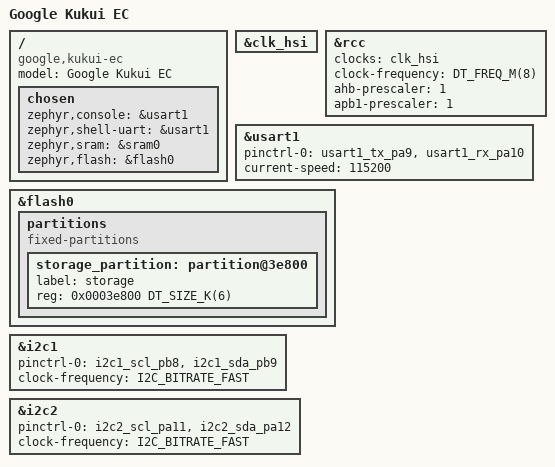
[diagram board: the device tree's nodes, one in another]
/*
 * Copyright (c) 2019 The Chromium OS Authors
 *
 * SPDX-License-Identifier: Apache-2.0
 */

/dts-v1/;
#include <st/f0/stm32f098Xc.dtsi>
#include <st/f0/stm32f098rchx-pinctrl.dtsi>

/ {
	model = "Google Kukui EC";
	compatible = "google,kukui-ec", "st,stm32f098";

	chosen {
		zephyr,console = &usart1;
		zephyr,shell-uart = &usart1;
		zephyr,sram = &sram0;
		zephyr,flash = &flash0;
	};
};

&clk_hsi {
	status = "okay";
};

&rcc {
	clocks = <&clk_hsi>;
	clock-frequency = <DT_FREQ_M(8)>;
	ahb-prescaler = <1>;
	apb1-prescaler = <1>;
};

&usart1 {
	pinctrl-0 = <&usart1_tx_pa9 &usart1_rx_pa10>;
	pinctrl-names = "default";
	current-speed = <115200>;
	status = "okay";
};

&flash0 {
	partitions {
		compatible = "fixed-partitions";
		#address-cells = <1>;
		#size-cells = <1>;

		/* Set 6Kb of storage at the end of the 256Kb of flash */
		storage_partition: partition@3e800 {
			label = "storage";
			reg = <0x0003e800 DT_SIZE_K(6)>;
		};
	};
};

&i2c1 {
	pinctrl-0 = <&i2c1_scl_pb8 &i2c1_sda_pb9>;
	pinctrl-names = "default";
	status = "okay";
	clock-frequency = <I2C_BITRATE_FAST>;
};

&i2c2 {
	pinctrl-0 = <&i2c2_scl_pa11 &i2c2_sda_pa12>;
	pinctrl-names = "default";
	status = "okay";
	clock-frequency = <I2C_BITRATE_FAST>;
};
